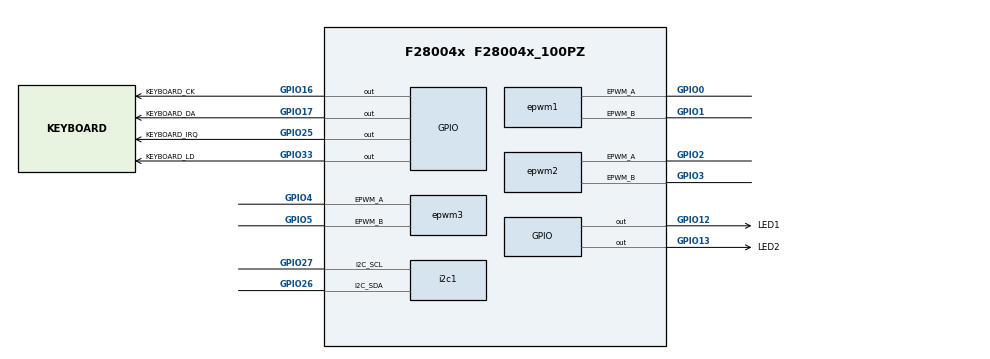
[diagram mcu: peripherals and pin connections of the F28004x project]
/**
 *
 * @cliArgs --device "F28004x" --part "F28004x_100PZ" --package "F28004x_100PZ" --context "system" --product "C2000WARE@26.00.00.00"
 * @versions {"tool":"1.28.0+4696"}
 */

/**
 * Import the modules used in this configuration.
 */
const adc         = scripting.addModule("/driverlib/adc.js", {}, false);
const adc1        = adc.addInstance();
const adc2        = adc.addInstance();
const asysctl     = scripting.addModule("/driverlib/asysctl.js");
const cputimer    = scripting.addModule("/driverlib/cputimer.js", {}, false);
const cputimer1   = cputimer.addInstance();
const epwm        = scripting.addModule("/driverlib/epwm.js", {}, false);
const epwm1       = epwm.addInstance();
const epwm2       = epwm.addInstance();
const epwm3       = epwm.addInstance();
const epwm4       = epwm.addInstance();
const epwm5       = epwm.addInstance();
const epwm6       = epwm.addInstance();
const gpio        = scripting.addModule("/driverlib/gpio.js", {}, false);
const gpio1       = gpio.addInstance();
const gpio2       = gpio.addInstance();
const gpio3       = gpio.addInstance();
const gpio4       = gpio.addInstance();
const gpio5       = gpio.addInstance();
const gpio6       = gpio.addInstance();
const i2c         = scripting.addModule("/driverlib/i2c.js", {}, false);
const i2c1        = i2c.addInstance();
const controller  = scripting.addModule("/libraries/control/dcl/controller.js", {}, false);
const controller1 = controller.addInstance();
const logger      = scripting.addModule("/libraries/control/dcl/logger.js", {}, false);
const logger1     = logger.addInstance();
const logger2     = logger.addInstance();
const logger3     = logger.addInstance();
const refgen      = scripting.addModule("/libraries/control/dcl/refgen.js", {}, false);
const refgen1     = refgen.addInstance();
const FPUfastRTS  = scripting.addModule("/libraries/math/FPUfastRTS/FPUfastRTS.js", {}, false);
const FPUfastRTS1 = FPUfastRTS.addInstance();

/**
 * Write custom configuration values to the imported modules.
 */
adc1.adcClockPrescaler              = "ADC_CLK_DIV_4_0";
adc1.socHighPriorityMode            = "ADC_PRI_ALL_HIPRI";
adc1.$name                          = "A0";
adc1.soc0SampleWindow               = 10;
adc1.soc0Trigger                    = "ADC_TRIGGER_EPWM1_SOCA";
adc1.interruptPulseMode             = "ADC_PULSE_END_OF_CONV";
adc1.enabledInts                    = ["ADC_INT_NUMBER1"];
adc1.enableInterrupt1               = true;
adc1.enableInterrupt1ContinuousMode = true;
adc1.registerInterrupts             = ["1"];
adc1.soc1SampleWindow               = 10;
adc1.soc1Trigger                    = "ADC_TRIGGER_EPWM1_SOCA";
adc1.soc2SampleWindow               = 10;
adc1.soc2Trigger                    = "ADC_TRIGGER_EPWM1_SOCA";
adc1.enabledSOCs                    = ["ADC_SOC_NUMBER0","ADC_SOC_NUMBER1","ADC_SOC_NUMBER2","ADC_SOC_NUMBER3","ADC_SOC_NUMBER4","ADC_SOC_NUMBER5"];
adc1.soc3Trigger                    = "ADC_TRIGGER_EPWM1_SOCA";
adc1.soc3SampleWindow               = 10;
adc1.soc4SampleWindow               = 10;
adc1.soc4Trigger                    = "ADC_TRIGGER_EPWM1_SOCA";
adc1.soc5SampleWindow               = 10;
adc1.soc5Trigger                    = "ADC_TRIGGER_EPWM1_SOCA";
adc1.interrupt1SOCSource            = "ADC_SOC_NUMBER5";
adc1.soc1Channel                    = "ADC_CH_ADCIN1";
adc1.soc2Channel                    = "ADC_CH_ADCIN2";
adc1.soc3Channel                    = "ADC_CH_ADCIN3";
adc1.soc4Channel                    = "ADC_CH_ADCIN4";
adc1.soc5Channel                    = "ADC_CH_ADCIN5";
adc1.adcInt1.enableInterrupt        = true;
adc1.adcInt1.interruptHandler       = "ADC_SamplingISR";

adc2.adcClockPrescaler   = "ADC_CLK_DIV_4_0";
adc2.socHighPriorityMode = "ADC_PRI_ALL_HIPRI";
adc2.$name               = "A1";
adc2.soc0SampleWindow    = 10;
adc2.soc0Trigger         = "ADC_TRIGGER_EPWM1_SOCA";
adc2.interruptPulseMode  = "ADC_PULSE_END_OF_CONV";
adc2.registerInterrupts  = ["1"];
adc2.soc1SampleWindow    = 10;
adc2.soc1Trigger         = "ADC_TRIGGER_EPWM1_SOCA";
adc2.soc2SampleWindow    = 10;
adc2.soc2Trigger         = "ADC_TRIGGER_EPWM1_SOCA";
adc2.soc3Channel         = "ADC_CH_ADCIN3";
adc2.soc3Trigger         = "ADC_TRIGGER_EPWM1_SOCA";
adc2.soc3SampleWindow    = 10;
adc2.soc4SampleWindow    = 10;
adc2.soc4Trigger         = "ADC_TRIGGER_EPWM1_SOCA";
adc2.soc5SampleWindow    = 10;
adc2.soc5Trigger         = "ADC_TRIGGER_EPWM1_SOCA";
adc2.soc4Channel         = "ADC_CH_ADCIN5";
adc2.soc5Channel         = "ADC_CH_ADCIN4";
adc2.adcBase             = "ADCB_BASE";
adc2.enabledSOCs         = ["ADC_SOC_NUMBER0","ADC_SOC_NUMBER1","ADC_SOC_NUMBER2","ADC_SOC_NUMBER3"];
adc2.interrupt1SOCSource = "ADC_SOC_NUMBER3";
adc2.useInterrupts       = false;
adc2.soc1Channel         = "ADC_CH_ADCIN1";
adc2.soc2Channel         = "ADC_CH_ADCIN2";

asysctl.analogReference        = "INTERNAL";
asysctl.analogReferenceVoltage = "1P65";

cputimer1.$name                    = "myCPUTIMER0";
cputimer1.enableInterrupt          = true;
cputimer1.registerInterrupts       = true;
cputimer1.startTimer               = true;
cputimer1.timerPeriod              = 99999;
cputimer1.timerInt.enableInterrupt = true;

const default_warning = scripting.addModule("/driverlib/default_warning.js", {}, false);
scripting.suppress("Add the \'Device Support\' module in order to use Clock Tree tool and generate device support files\\. This suggestion can be ignored if not using the Clock Tree tool\\.", default_warning);

epwm1.$name                                                      = "EPWMA";
epwm1.epwmTimebase_hsClockDiv                                    = "EPWM_HSCLOCK_DIVIDER_1";
epwm1.epwmTimebase_counterMode                                   = "EPWM_COUNTER_MODE_UP_DOWN";
epwm1.epwmTimebase_syncOutPulseMode                              = "EPWM_SYNC_OUT_PULSE_ON_COUNTER_ZERO";
epwm1.epwmTimebase_forceSyncPulse                                = true;
epwm1.epwmCounterCompare_cmpA                                    = 1250;
epwm1.epwmDeadband_polarityFED                                   = "EPWM_DB_POLARITY_ACTIVE_LOW";
epwm1.epwmDeadband_enableRED                                     = true;
epwm1.epwmDeadband_delayRED                                      = 20;
epwm1.epwmDeadband_enableFED                                     = true;
epwm1.epwmDeadband_delayFED                                      = 20;
epwm1.epwmEventTrigger_interruptSource                           = "EPWM_INT_TBCTR_PERIOD";
epwm1.epwmEventTrigger_interruptEventCount                       = "1";
epwm1.epwmActionQualifier_EPWM_AQ_OUTPUT_A_shadowMode            = true;
epwm1.epwmActionQualifier_EPWM_AQ_OUTPUT_B_shadowMode            = true;
epwm1.epwmActionQualifier_EPWM_AQ_OUTPUT_A_ON_TIMEBASE_UP_CMPA   = "EPWM_AQ_OUTPUT_LOW";
epwm1.epwmActionQualifier_EPWM_AQ_OUTPUT_A_ON_TIMEBASE_DOWN_CMPA = "EPWM_AQ_OUTPUT_HIGH";
epwm1.epwmActionQualifier_EPWM_AQ_OUTPUT_B_ON_TIMEBASE_UP_CMPA   = "EPWM_AQ_OUTPUT_LOW";
epwm1.epwmActionQualifier_EPWM_AQ_OUTPUT_B_ON_TIMEBASE_DOWN_CMPA = "EPWM_AQ_OUTPUT_HIGH";
epwm1.epwmEventTrigger_EPWM_SOC_A_triggerEnable                  = true;
epwm1.epwmEventTrigger_EPWM_SOC_A_triggerSource                  = "EPWM_SOC_TBCTR_ZERO";
epwm1.epwmEventTrigger_EPWM_SOC_A_triggerEventPrescalar          = "1";
epwm1.epwmCounterCompare_cmpB                                    = 1250;
epwm1.epwmTimebase_period                                        = 2500;
epwm1.epwmTripZone_EPWM_TZ_ACTION_EVENT_TZA                      = "EPWM_TZ_ACTION_LOW";
epwm1.epwmTripZone_EPWM_TZ_ACTION_EVENT_TZB                      = "EPWM_TZ_ACTION_LOW";
epwm1.hrpwm_syncSource                                           = "HRPWM_PWMSYNC_SOURCE_ZERO";
epwm1.epwm.$assign                                               = "EPWM1";
epwm1.epwm.epwm_aPin.$assign                                     = "GPIO0";
epwm1.epwm.epwm_bPin.$assign                                     = "GPIO1";

epwm2.$name                                                      = "EPWMB";
epwm2.epwmTimebase_hsClockDiv                                    = "EPWM_HSCLOCK_DIVIDER_1";
epwm2.copyFrom                                                   = "EPWMA";
epwm2.epwmTimebase_period                                        = 2500;
epwm2.epwmTimebase_counterMode                                   = "EPWM_COUNTER_MODE_UP_DOWN";
epwm2.epwmCounterCompare_cmpA                                    = 1250;
epwm2.epwmCounterCompare_cmpB                                    = 1250;
epwm2.epwmActionQualifier_EPWM_AQ_OUTPUT_A_shadowMode            = true;
epwm2.epwmActionQualifier_EPWM_AQ_OUTPUT_A_ON_TIMEBASE_UP_CMPA   = "EPWM_AQ_OUTPUT_LOW";
epwm2.epwmActionQualifier_EPWM_AQ_OUTPUT_A_ON_TIMEBASE_DOWN_CMPA = "EPWM_AQ_OUTPUT_HIGH";
epwm2.epwmActionQualifier_EPWM_AQ_OUTPUT_B_shadowMode            = true;
epwm2.epwmActionQualifier_EPWM_AQ_OUTPUT_B_ON_TIMEBASE_UP_CMPA   = "EPWM_AQ_OUTPUT_LOW";
epwm2.epwmActionQualifier_EPWM_AQ_OUTPUT_B_ON_TIMEBASE_DOWN_CMPA = "EPWM_AQ_OUTPUT_HIGH";
epwm2.epwmDeadband_polarityFED                                   = "EPWM_DB_POLARITY_ACTIVE_LOW";
epwm2.epwmDeadband_enableRED                                     = true;
epwm2.epwmDeadband_delayRED                                      = 20;
epwm2.epwmDeadband_enableFED                                     = true;
epwm2.epwmDeadband_delayFED                                      = 20;
epwm2.epwmTripZone_EPWM_TZ_ACTION_EVENT_TZA                      = "EPWM_TZ_ACTION_LOW";
epwm2.epwmTripZone_EPWM_TZ_ACTION_EVENT_TZB                      = "EPWM_TZ_ACTION_LOW";
epwm2.epwmEventTrigger_interruptSource                           = "EPWM_INT_TBCTR_PERIOD";
epwm2.epwmEventTrigger_interruptEventCount                       = "1";
epwm2.hrpwm_syncSource                                           = "HRPWM_PWMSYNC_SOURCE_ZERO";
epwm2.epwmTimebase_counterModeAfterSync                          = "EPWM_COUNT_MODE_UP_AFTER_SYNC";
epwm2.epwmTimebase_phaseEnable                                   = true;
epwm2.epwmTimebase_syncOutPulseMode                              = "EPWM_SYNC_OUT_PULSE_ON_EPWMxSYNCIN";
epwm2.epwm.$assign                                               = "EPWM2";
epwm2.epwm.epwm_aPin.$assign                                     = "GPIO2";
epwm2.epwm.epwm_bPin.$assign                                     = "GPIO3";

epwm3.$name                                                      = "EPWMC";
epwm3.copyFrom                                                   = "EPWMB";
epwm3.epwmTimebase_hsClockDiv                                    = "EPWM_HSCLOCK_DIVIDER_1";
epwm3.epwmTimebase_period                                        = 2500;
epwm3.epwmTimebase_counterMode                                   = "EPWM_COUNTER_MODE_UP_DOWN";
epwm3.epwmTimebase_counterModeAfterSync                          = "EPWM_COUNT_MODE_UP_AFTER_SYNC";
epwm3.epwmTimebase_phaseEnable                                   = true;
epwm3.epwmTimebase_syncOutPulseMode                              = "EPWM_SYNC_OUT_PULSE_ON_EPWMxSYNCIN";
epwm3.hrpwm_syncSource                                           = "HRPWM_PWMSYNC_SOURCE_ZERO";
epwm3.epwmCounterCompare_cmpA                                    = 1250;
epwm3.epwmCounterCompare_cmpB                                    = 1250;
epwm3.epwmActionQualifier_EPWM_AQ_OUTPUT_A_shadowMode            = true;
epwm3.epwmActionQualifier_EPWM_AQ_OUTPUT_A_ON_TIMEBASE_UP_CMPA   = "EPWM_AQ_OUTPUT_LOW";
epwm3.epwmActionQualifier_EPWM_AQ_OUTPUT_A_ON_TIMEBASE_DOWN_CMPA = "EPWM_AQ_OUTPUT_HIGH";
epwm3.epwmActionQualifier_EPWM_AQ_OUTPUT_B_shadowMode            = true;
epwm3.epwmActionQualifier_EPWM_AQ_OUTPUT_B_ON_TIMEBASE_UP_CMPA   = "EPWM_AQ_OUTPUT_LOW";
epwm3.epwmActionQualifier_EPWM_AQ_OUTPUT_B_ON_TIMEBASE_DOWN_CMPA = "EPWM_AQ_OUTPUT_HIGH";
epwm3.epwmDeadband_polarityFED                                   = "EPWM_DB_POLARITY_ACTIVE_LOW";
epwm3.epwmDeadband_enableRED                                     = true;
epwm3.epwmDeadband_delayRED                                      = 20;
epwm3.epwmDeadband_enableFED                                     = true;
epwm3.epwmDeadband_delayFED                                      = 20;
epwm3.epwmTripZone_EPWM_TZ_ACTION_EVENT_TZA                      = "EPWM_TZ_ACTION_LOW";
epwm3.epwmTripZone_EPWM_TZ_ACTION_EVENT_TZB                      = "EPWM_TZ_ACTION_LOW";
epwm3.epwmEventTrigger_interruptSource                           = "EPWM_INT_TBCTR_PERIOD";
epwm3.epwmEventTrigger_interruptEventCount                       = "1";
epwm3.epwm.$assign                                               = "EPWM3";
epwm3.epwm.epwm_aPin.$assign                                     = "GPIO4";
epwm3.epwm.epwm_bPin.$assign                                     = "GPIO5";

epwm4.copyFrom                                                   = "EPWMB";
epwm4.epwmTimebase_hsClockDiv                                    = "EPWM_HSCLOCK_DIVIDER_1";
epwm4.epwmTimebase_period                                        = 2500;
epwm4.epwmTimebase_counterMode                                   = "EPWM_COUNTER_MODE_UP_DOWN";
epwm4.epwmTimebase_counterModeAfterSync                          = "EPWM_COUNT_MODE_UP_AFTER_SYNC";
epwm4.epwmTimebase_phaseEnable                                   = true;
epwm4.epwmTimebase_syncOutPulseMode                              = "EPWM_SYNC_OUT_PULSE_ON_EPWMxSYNCIN";
epwm4.hrpwm_syncSource                                           = "HRPWM_PWMSYNC_SOURCE_ZERO";
epwm4.epwmCounterCompare_cmpA                                    = 1250;
epwm4.epwmCounterCompare_cmpB                                    = 1250;
epwm4.epwmActionQualifier_EPWM_AQ_OUTPUT_A_shadowMode            = true;
epwm4.epwmActionQualifier_EPWM_AQ_OUTPUT_A_ON_TIMEBASE_UP_CMPA   = "EPWM_AQ_OUTPUT_LOW";
epwm4.epwmActionQualifier_EPWM_AQ_OUTPUT_A_ON_TIMEBASE_DOWN_CMPA = "EPWM_AQ_OUTPUT_HIGH";
epwm4.epwmActionQualifier_EPWM_AQ_OUTPUT_B_shadowMode            = true;
epwm4.epwmActionQualifier_EPWM_AQ_OUTPUT_B_ON_TIMEBASE_UP_CMPA   = "EPWM_AQ_OUTPUT_LOW";
epwm4.epwmActionQualifier_EPWM_AQ_OUTPUT_B_ON_TIMEBASE_DOWN_CMPA = "EPWM_AQ_OUTPUT_HIGH";
epwm4.epwmDeadband_polarityFED                                   = "EPWM_DB_POLARITY_ACTIVE_LOW";
epwm4.epwmDeadband_enableRED                                     = true;
epwm4.epwmDeadband_delayRED                                      = 20;
epwm4.epwmDeadband_enableFED                                     = true;
epwm4.epwmDeadband_delayFED                                      = 20;
epwm4.epwmTripZone_EPWM_TZ_ACTION_EVENT_TZA                      = "EPWM_TZ_ACTION_LOW";
epwm4.epwmTripZone_EPWM_TZ_ACTION_EVENT_TZB                      = "EPWM_TZ_ACTION_LOW";
epwm4.epwmEventTrigger_interruptSource                           = "EPWM_INT_TBCTR_PERIOD";
epwm4.epwmEventTrigger_interruptEventCount                       = "1";
epwm4.$name                                                      = "EPWMD";
epwm4.epwm.$assign                                               = "EPWM4";

epwm5.copyFrom                                                   = "EPWMB";
epwm5.epwmTimebase_hsClockDiv                                    = "EPWM_HSCLOCK_DIVIDER_1";
epwm5.epwmTimebase_period                                        = 2500;
epwm5.epwmTimebase_counterMode                                   = "EPWM_COUNTER_MODE_UP_DOWN";
epwm5.epwmTimebase_counterModeAfterSync                          = "EPWM_COUNT_MODE_UP_AFTER_SYNC";
epwm5.epwmTimebase_phaseEnable                                   = true;
epwm5.epwmTimebase_syncOutPulseMode                              = "EPWM_SYNC_OUT_PULSE_ON_EPWMxSYNCIN";
epwm5.hrpwm_syncSource                                           = "HRPWM_PWMSYNC_SOURCE_ZERO";
epwm5.epwmCounterCompare_cmpA                                    = 1250;
epwm5.epwmCounterCompare_cmpB                                    = 1250;
epwm5.epwmActionQualifier_EPWM_AQ_OUTPUT_A_shadowMode            = true;
epwm5.epwmActionQualifier_EPWM_AQ_OUTPUT_A_ON_TIMEBASE_UP_CMPA   = "EPWM_AQ_OUTPUT_LOW";
epwm5.epwmActionQualifier_EPWM_AQ_OUTPUT_A_ON_TIMEBASE_DOWN_CMPA = "EPWM_AQ_OUTPUT_HIGH";
epwm5.epwmActionQualifier_EPWM_AQ_OUTPUT_B_shadowMode            = true;
epwm5.epwmActionQualifier_EPWM_AQ_OUTPUT_B_ON_TIMEBASE_UP_CMPA   = "EPWM_AQ_OUTPUT_LOW";
epwm5.epwmActionQualifier_EPWM_AQ_OUTPUT_B_ON_TIMEBASE_DOWN_CMPA = "EPWM_AQ_OUTPUT_HIGH";
epwm5.epwmDeadband_polarityFED                                   = "EPWM_DB_POLARITY_ACTIVE_LOW";
epwm5.epwmDeadband_enableRED                                     = true;
epwm5.epwmDeadband_delayRED                                      = 20;
epwm5.epwmDeadband_enableFED                                     = true;
epwm5.epwmDeadband_delayFED                                      = 20;
epwm5.epwmTripZone_EPWM_TZ_ACTION_EVENT_TZA                      = "EPWM_TZ_ACTION_LOW";
epwm5.epwmTripZone_EPWM_TZ_ACTION_EVENT_TZB                      = "EPWM_TZ_ACTION_LOW";
epwm5.epwmEventTrigger_interruptSource                           = "EPWM_INT_TBCTR_PERIOD";
epwm5.epwmEventTrigger_interruptEventCount                       = "1";
epwm5.$name                                                      = "EPWME";

epwm6.copyFrom                                                   = "EPWMB";
epwm6.epwmTimebase_hsClockDiv                                    = "EPWM_HSCLOCK_DIVIDER_1";
epwm6.epwmTimebase_period                                        = 2500;
epwm6.epwmTimebase_counterMode                                   = "EPWM_COUNTER_MODE_UP_DOWN";
epwm6.epwmTimebase_counterModeAfterSync                          = "EPWM_COUNT_MODE_UP_AFTER_SYNC";
epwm6.epwmTimebase_phaseEnable                                   = true;
epwm6.epwmTimebase_syncOutPulseMode                              = "EPWM_SYNC_OUT_PULSE_ON_EPWMxSYNCIN";
epwm6.hrpwm_syncSource                                           = "HRPWM_PWMSYNC_SOURCE_ZERO";
epwm6.epwmCounterCompare_cmpA                                    = 1250;
epwm6.epwmCounterCompare_cmpB                                    = 1250;
epwm6.epwmActionQualifier_EPWM_AQ_OUTPUT_A_shadowMode            = true;
epwm6.epwmActionQualifier_EPWM_AQ_OUTPUT_A_ON_TIMEBASE_UP_CMPA   = "EPWM_AQ_OUTPUT_LOW";
epwm6.epwmActionQualifier_EPWM_AQ_OUTPUT_A_ON_TIMEBASE_DOWN_CMPA = "EPWM_AQ_OUTPUT_HIGH";
epwm6.epwmActionQualifier_EPWM_AQ_OUTPUT_B_shadowMode            = true;
epwm6.epwmActionQualifier_EPWM_AQ_OUTPUT_B_ON_TIMEBASE_UP_CMPA   = "EPWM_AQ_OUTPUT_LOW";
epwm6.epwmActionQualifier_EPWM_AQ_OUTPUT_B_ON_TIMEBASE_DOWN_CMPA = "EPWM_AQ_OUTPUT_HIGH";
epwm6.epwmDeadband_polarityFED                                   = "EPWM_DB_POLARITY_ACTIVE_LOW";
epwm6.epwmDeadband_enableRED                                     = true;
epwm6.epwmDeadband_delayRED                                      = 20;
epwm6.epwmDeadband_enableFED                                     = true;
epwm6.epwmDeadband_delayFED                                      = 20;
epwm6.epwmTripZone_EPWM_TZ_ACTION_EVENT_TZA                      = "EPWM_TZ_ACTION_LOW";
epwm6.epwmTripZone_EPWM_TZ_ACTION_EVENT_TZB                      = "EPWM_TZ_ACTION_LOW";
epwm6.epwmEventTrigger_interruptSource                           = "EPWM_INT_TBCTR_PERIOD";
epwm6.epwmEventTrigger_interruptEventCount                       = "1";
epwm6.$name                                                      = "EPWMF";
epwm6.epwm.$assign                                               = "EPWM6";

gpio1.$name           = "KEYBOARD_LD";
gpio1.direction       = "GPIO_DIR_MODE_OUT";
gpio1.gpioPin.$assign = "GPIO33";

gpio2.$name           = "KEYBOARD_CK";
gpio2.direction       = "GPIO_DIR_MODE_OUT";
gpio2.gpioPin.$assign = "GPIO16";

gpio3.$name           = "KEYBOARD_DA";
gpio3.gpioPin.$assign = "GPIO17";

gpio4.$name           = "KEYBOARD_IRQ";
gpio4.gpioPin.$assign = "GPIO25";

gpio5.direction         = "GPIO_DIR_MODE_OUT";
gpio5.writeInitialValue = true;
gpio5.initialValue      = 1;
gpio5.$name             = "LED1";
gpio5.gpioPin.$assign   = "GPIO12";

gpio6.direction         = "GPIO_DIR_MODE_OUT";
gpio6.writeInitialValue = true;
gpio6.$name             = "LED2";
gpio6.gpioPin.$assign   = "GPIO13";

i2c1.$name                  = "myI2C0";
i2c1.useInterfacePins       = ["I2C@_SCL","I2C@_SDA"];
i2c1.dataCount              = 2;
i2c1.bitCount               = "I2C_BITCOUNT_8";
i2c1.i2c.i2c_sdaPin.$assign = "GPIO26";
i2c1.i2c.i2c_sclPin.$assign = "GPIO27";

controller1.$name = "myCONTROLLER0";

logger1.$name     = "myLOGGER0";
logger1.linkerEn  = true;
logger1.linkerVal = "logVariables";
logger1.logSize   = 400;

logger2.$name     = "myLOGGER1";
logger2.linkerEn  = true;
logger2.linkerVal = "logVariables";
logger2.logSize   = 400;

logger3.$name     = "myLOGGER2";
logger3.linkerEn  = true;
logger3.linkerVal = "logVariables";
logger3.logSize   = 400;

refgen1.$name   = "theta_REFGEN";
refgen1.mode    = "SAW";
refgen1.sampPer = 0.00005;
refgen1.freq    = 50;
refgen1.umax    = 1;
refgen1.offs    = 0;

FPUfastRTS1.$name = "myFFR0";

/**
 * Pinmux solution for unlocked pins/peripherals. This ensures that minor changes to the automatic solver in a future
 * version of the tool will not impact the pinmux you originally saw.  These lines can be completely deleted in order to
 * re-solve from scratch.
 */
epwm4.epwm.epwm_aPin.$suggestSolution = "GPIO6";
epwm4.epwm.epwm_bPin.$suggestSolution = "GPIO7";
epwm5.epwm.$suggestSolution           = "EPWM5";
epwm5.epwm.epwm_aPin.$suggestSolution = "GPIO8";
epwm5.epwm.epwm_bPin.$suggestSolution = "GPIO9";
epwm6.epwm.epwm_aPin.$suggestSolution = "GPIO10";
epwm6.epwm.epwm_bPin.$suggestSolution = "GPIO11";
i2c1.i2c.$suggestSolution             = "I2CA";
